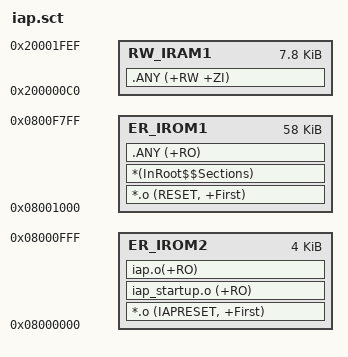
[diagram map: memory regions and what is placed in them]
; *************************************************************
; *** Scatter-Loading Description File generated by uVision ***
; *************************************************************


LR_IROM2 0x08000000 0x00001000  {    ; load region size_region
  ER_IROM2 0x08000000 0x00001000  {  ; load address = execution address
   *.o (IAPRESET, +First)
   iap_startup.o (+RO)
   iap.o(+RO)
  }
  ;RW_IRAM2 0x20000000 0x000000c0  {  ; RW data
;   iap.o (sramvector)
  ;}
}

LR_IROM1 0x08001000 0x0000E800  {    ; load region size_region
  ER_IROM1 0x08001000 0x0000E800  {  ; load address = execution address
   *.o (RESET, +First)
   *(InRoot$$Sections)
   .ANY (+RO)
  }
  RW_IRAM1 0x200000c0 0x00001F30  {  ; RW data
   .ANY (+RW +ZI)
  }
}
